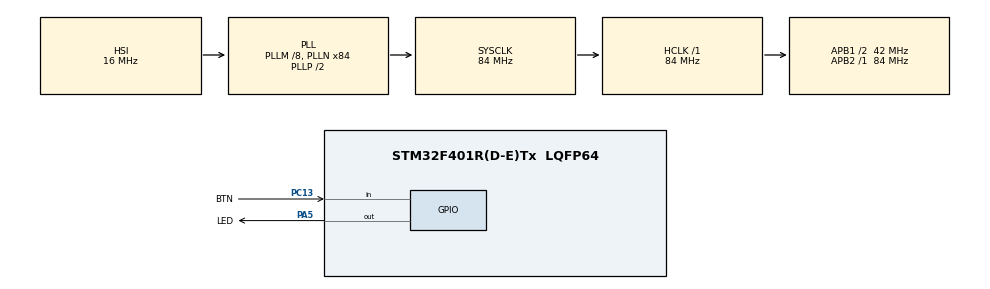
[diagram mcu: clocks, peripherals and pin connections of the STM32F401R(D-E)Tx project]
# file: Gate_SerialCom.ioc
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Mcu.Family=STM32F4
Mcu.Name=STM32F401R(D-E)Tx
Mcu.Package=LQFP64
NVIC.PriorityGroup=NVIC_PRIORITYGROUP_4
PA5.GPIO_Label=LED
PA5.Signal=GPIO_Output
PC13-ANTI_TAMP.GPIO_Label=BTN
PC13-ANTI_TAMP.Signal=GPIO_Input
ProjectManager.HeapSize=0x0
ProjectManager.StackSize=0x400
ProjectManager.TargetToolchain=Other Toolchains (GPDSC)
RCC.48MHZClocksFreq_Value=42000000
RCC.AHBFreq_Value=84000000
RCC.APB1CLKDivider=RCC_HCLK_DIV2
RCC.APB1Freq_Value=42000000
RCC.APB1TimFreq_Value=84000000
RCC.APB2Freq_Value=84000000
RCC.APB2TimFreq_Value=84000000
RCC.CortexFreq_Value=84000000
RCC.HCLKFreq_Value=84000000
RCC.HSE_VALUE=25000000
RCC.HSI_VALUE=16000000
RCC.LSE_VALUE=32768
RCC.PLLM=8
RCC.PLLN=84
RCC.SYSCLKFreq_VALUE=84000000
RCC.SYSCLKSource=RCC_SYSCLKSOURCE_PLLCLK
RCC.VCOOutputFreq_Value=168000000
board=custom

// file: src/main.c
/* USER CODE BEGIN Header */
/**
 ******************************************************************************
 * @file           : main.c
 * @brief          : Main program body
 ******************************************************************************
 * @attention
 *
 * <h2><center>&copy; Copyright (c) 2021 STMicroelectronics.
 * All rights reserved.</center></h2>
 *
 * This software component is licensed by ST under BSD 3-Clause license,
 * the "License"; You may not use this file except in compliance with the
 * License. You may obtain a copy of the License at:
 *                        opensource.org/licenses/BSD-3-Clause
 *
 ******************************************************************************
 */
/* USER CODE END Header */
#include "main.h"
#include "gpio.h"

/* USER CODE BEGIN Includes */
#include "luos_engine.h"
#include "robus_network.h"
#include "gate.h"
#include "pipe.h"
/* USER CODE END Includes */

void SystemClock_Config(void);

int main(void)
{

    /* MCU Configuration--------------------------------------------------------*/

    /* Reset of all peripherals, Initializes the Flash interface and the Systick. */
    HAL_Init();

    /* Configure the system clock */
    SystemClock_Config();

    /* Initialize all configured peripherals */
    MX_GPIO_Init();
    /* USER CODE BEGIN 2 */
    Luos_Init();
    Robus_Init();
    Gate_Init();
    Pipe_Init();
    /* USER CODE END 2 */

    /* Infinite loop */
    while (1)
    {

        /* USER CODE BEGIN 3 */
        Luos_Loop();
        Gate_Loop();
        Pipe_Loop();
    }
    /* USER CODE END 3 */
}

void SystemClock_Config(void)
{
    RCC_OscInitTypeDef RCC_OscInitStruct = {0};
    RCC_ClkInitTypeDef RCC_ClkInitStruct = {0};

    /** Configure the main internal regulator output voltage
     */
    __HAL_RCC_PWR_CLK_ENABLE();
    __HAL_PWR_VOLTAGESCALING_CONFIG(PWR_REGULATOR_VOLTAGE_SCALE2);
    /** Initializes the RCC Oscillators according to the specified parameters
     * in the RCC_OscInitTypeDef structure.
     */
    RCC_OscInitStruct.OscillatorType      = RCC_OSCILLATORTYPE_HSI;
    RCC_OscInitStruct.HSIState            = RCC_HSI_ON;
    RCC_OscInitStruct.HSICalibrationValue = RCC_HSICALIBRATION_DEFAULT;
    RCC_OscInitStruct.PLL.PLLState        = RCC_PLL_ON;
    RCC_OscInitStruct.PLL.PLLSource       = RCC_PLLSOURCE_HSI;
    RCC_OscInitStruct.PLL.PLLM            = 8;
    RCC_OscInitStruct.PLL.PLLN            = 84;
    RCC_OscInitStruct.PLL.PLLP            = RCC_PLLP_DIV2;
    RCC_OscInitStruct.PLL.PLLQ            = 4;
    if (HAL_RCC_OscConfig(&RCC_OscInitStruct) != HAL_OK)
    {
        Error_Handler();
    }
    /** Initializes the CPU, AHB and APB buses clocks
     */
    RCC_ClkInitStruct.ClockType = RCC_CLOCKTYPE_HCLK | RCC_CLOCKTYPE_SYSCLK
                                  | RCC_CLOCKTYPE_PCLK1 | RCC_CLOCKTYPE_PCLK2;
    RCC_ClkInitStruct.SYSCLKSource   = RCC_SYSCLKSOURCE_PLLCLK;
    RCC_ClkInitStruct.AHBCLKDivider  = RCC_SYSCLK_DIV1;
    RCC_ClkInitStruct.APB1CLKDivider = RCC_HCLK_DIV2;
    RCC_ClkInitStruct.APB2CLKDivider = RCC_HCLK_DIV1;

    if (HAL_RCC_ClockConfig(&RCC_ClkInitStruct, FLASH_LATENCY_2) != HAL_OK)
    {
        Error_Handler();
    }
}

void Error_Handler(void)
{
    __disable_irq();
    while (1)
    {
    }
}

/************************ (C) COPYRIGHT STMicroelectronics *****END OF FILE****/
